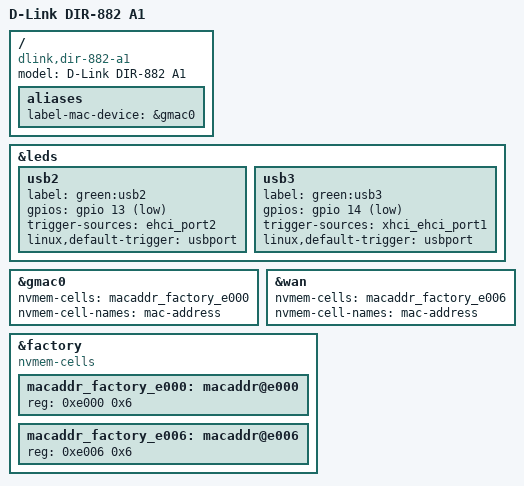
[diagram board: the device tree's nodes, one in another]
// SPDX-License-Identifier: GPL-2.0-or-later OR MIT

#include "mt7621_dlink_dir-8xx.dtsi"
#include "mt7621_dlink_flash-16m-a1.dtsi"

/ {
	compatible = "dlink,dir-882-a1", "mediatek,mt7621-soc";
	model = "D-Link DIR-882 A1";

	aliases {
		label-mac-device = &gmac0;
	};
};

&leds {
	usb2 {
		label = "green:usb2";
		gpios = <&gpio 13 GPIO_ACTIVE_LOW>;
		trigger-sources = <&ehci_port2>;
		linux,default-trigger = "usbport";
	};

	usb3 {
		label = "green:usb3";
		gpios = <&gpio 14 GPIO_ACTIVE_LOW>;
		trigger-sources = <&xhci_ehci_port1>;
		linux,default-trigger = "usbport";
	};
};

&gmac0 {
	nvmem-cells = <&macaddr_factory_e000>;
	nvmem-cell-names = "mac-address";
};

&wan {
	nvmem-cells = <&macaddr_factory_e006>;
	nvmem-cell-names = "mac-address";
};

&factory {
	compatible = "nvmem-cells";
	#address-cells = <1>;
	#size-cells = <1>;

	macaddr_factory_e000: macaddr@e000 {
		reg = <0xe000 0x6>;
	};

	macaddr_factory_e006: macaddr@e006 {
		reg = <0xe006 0x6>;
	};
};
